# R7FA4L1BD register map
Vendor: Renesas Electronics Corporation; Series: RA4; File version: 1.20.03
CPU: CM33 r0p4, little endian, MPU, FPU, VTOR, 4 interrupt priority bits, 96 interrupts
Registers are 32-bit, read-write, reset 0x0 unless marked. A register's access mark holds for its fields unless they carry their own. Offsets are from the block's base; [hi:lo] are bit positions; {n}, {i} and the like mark numbered series; 'fields as' and 'values as' point back to an identical list.

## CACHE
Base 0x40007000
0x00 CCACTL — C-Cache Control Register
  [0] ENC — C-Cache Enable
    0=Disable C-cache; 1=Enable C-cache
0x04 CCAFCT — C-Cache Flush Control Register
  [0] FC — C-Cache Flush
    0=No action; 1=C-cache line flush (all lines invalidated)
0x08 CCALCF reset 0x1 — C-Cache Line Configuration Register
  [1:0] CC — C-Cache Line Size
    0=Prohibited; 1=Cache line size 32 bytes; 2=Cache line size 64 bytes; 3=Prohibited
0x40 SCACTL — S-Cache Control Register
  [0] ENS — S-Cache Enable
    0=Disable S-cache; 1=Enable S-cache
0x44 SCAFCT — S-Cache Flush Control Register
  [0] FS — S-Cache Flush
    0=No action; 1=S-cache line flush (all lines invalidated)
0x48 SCALCF reset 0x1 — S-Cache Line Configuration Register
  [1:0] CS — S-Cache Line Size
    values as CCALCF.CC
0x200 CAPOAD — Cache Parity Error Operation After Detection Register
  [0] OAD — Operation after Detection
    0=Non-maskable interrupt; 1=Reset
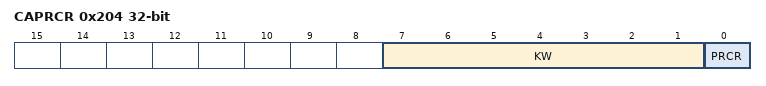
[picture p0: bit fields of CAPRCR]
0x204 CAPRCR — Cache Protection Register
  [7:1] KW — Write key code
  [0] PRCR — Register Write Control
    0=Disable writes to protected registers; 1=Enable writes to protected registers

## DBG — Debug Function
Base 0x4001B000
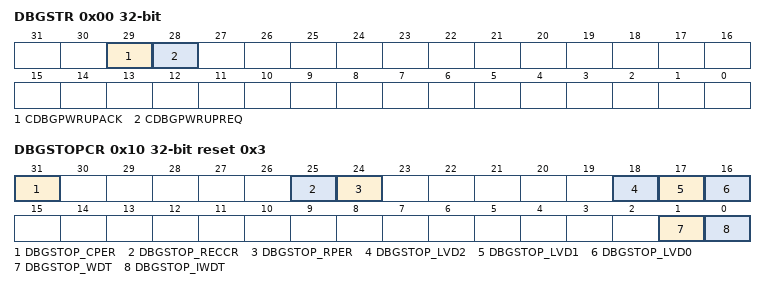
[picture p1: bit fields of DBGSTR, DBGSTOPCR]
0x00 DBGSTR ro — Debug Status Register
  [29] CDBGPWRUPACK — Debug power-up acknowledge
    0=Debug power-up request is not acknowledged; 1=Debug power-up request is acknowledged
  [28] CDBGPWRUPREQ — Debug power-up request
    0=OCD is not requesting debug power up; 1=OCD is requesting debug power up
0x10 DBGSTOPCR reset 0x3 — Debug Stop Control Register
  [31] DBGSTOP_CPER — Mask bit for Cache SRAM parity error reset/interrupt
    0=Enable Cache SRAM parity error reset/interrupt; 1=Mask Cache SRAM parity error reset/interrupt
  [25] DBGSTOP_RECCR — Mask bit for SRAM ECC error reset/interrupt
    0=Enable SRAM ECC error reset/interrupt; 1=Mask SRAM ECC error reset/interrupt
  [24] DBGSTOP_RPER — Mask bit for SRAM parity error reset/interrupt
    0=Enable SRAM parity error reset/interrupt; 1=Mask SRAM parity error reset/interrupt
  [18] DBGSTOP_LVD2 — Mask bit for LVD2 reset/interrupt
    0=Enable LVD2 reset/interrupt; 1=Mask LVD2 reset/interrupt
  [17] DBGSTOP_LVD1 — Mask bit for LVD1 reset/interrupt
    0=Enable LVD1 reset/interrupt; 1=Mask LVD1 reset/interrupt
  [16] DBGSTOP_LVD0 — Mask bit for LVD0 reset
    0=Enable LVD0 reset; 1=Mask LVD0 reset
  [1] DBGSTOP_WDT — Mask bit for WDT reset/interrupt in the OCD run mode
    0=Enable WDT reset/interrupt; 1=Mask WDT reset/interrupt and stop WDT counter
  [0] DBGSTOP_IWDT — Mask bit for IWDT reset/interrupt in the OCD run mode
    0=Enable IWDT reset/interrupt; 1=Mask IWDT reset/interrupt and stop IWDT counter

## FCACHE — SYSTEM/FLASH
Base 0x4001C100
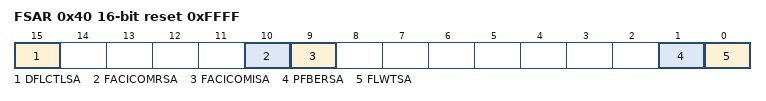
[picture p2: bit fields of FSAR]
0x40 FSAR 16-bit reset 0xFFFF — Flash Security Attribution Register
  [all] fields
    0=Secure; 1=Non-secure
  [15] DFLCTLSA — DFLCTL Security Attribution
  [10] FACICOMRSA — FACI Command Registers Security Attribution
  [9] FACICOMISA — FACI Command Issuing Security Attribution
  [1] PFBERSA — PFBER Security Attribution
  [0] FLWTSA — FLWT Security Attribution

## PORT0 — Pmn Pin FunctionPort 0 Control RegistersPmn Pin Function Control Register
Base 0x4001F000
Same registers: PORT5 0x4001F0A0, PORT8 0x4001F100
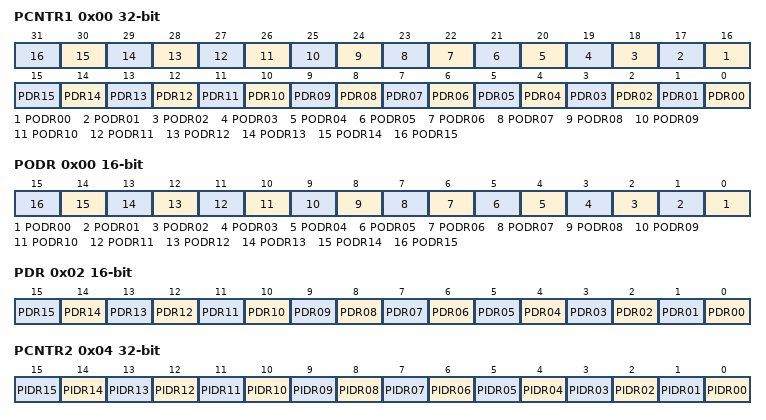
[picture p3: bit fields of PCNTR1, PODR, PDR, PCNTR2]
0x00 PCNTR1 — Port Control Register 1
  [n+16] PODR{n:02} (n=0..15) — Pmn Output Data
    0=Low output; 1=High output
  [n] PDR{n:02} (n=0..15) — Pmn Direction
    0=Input (functions as an input pin); 1=Output (functions as an output pin)
0x00 PODR 16-bit (alternate view of PCNTR1) — Port Control Register 1
  [all] fields
    0=Low output; 1=High output
  [n] PODR{n:02} (n=0..15) — Pmn Output Data
0x02 PDR 16-bit (alternate view of PCNTR1) — Port Control Register 1
  [all] fields
    values as PCNTR1.PDR00
  [n] PDR{n:02} (n=0..15) — Pmn Direction
0x04 PCNTR2 ro (reset mask 0xFFFF0000) — Port Control Register 2
  [all] fields
    0=Low level; 1=High level
  [n] PIDR{n:02} (n=0..15) — Pmn State
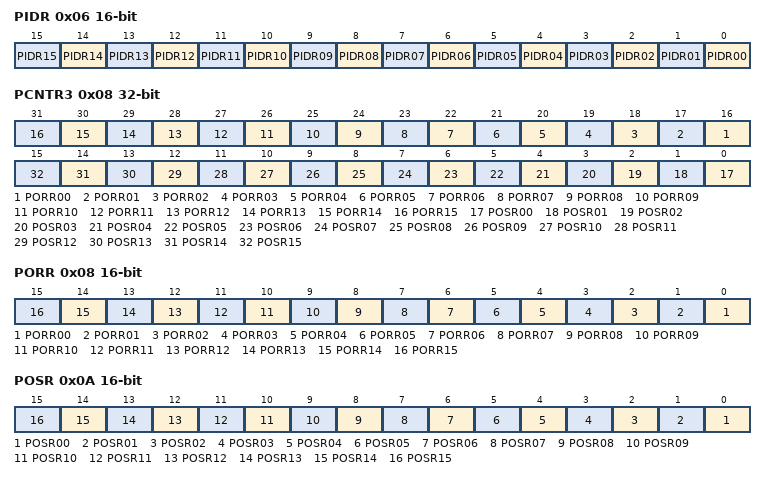
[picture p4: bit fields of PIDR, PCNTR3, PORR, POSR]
0x06 PIDR 16-bit ro reset not defined (alternate view of PCNTR2) — Port Control Register 2
  fields as PCNTR2
0x08 PCNTR3 wo — Port Control Register 3
  [n+16] PORR{n:02} (n=0..15) — Pmn Output Reset
    0=No effect on output; 1=Low output
  [n] POSR{n:02} (n=0..15) — Pmn Output Set
    0=No effect on output; 1=High output
0x08 PORR 16-bit wo (alternate view of PCNTR3) — Port Control Register 3
  [all] fields
    0=No effect on output; 1=Low output
  [n] PORR{n:02} (n=0..15) — Pmn Output Reset
0x0A POSR 16-bit wo (alternate view of PCNTR3) — Port Control Register 3
  [all] fields
    0=No effect on output; 1=High output
  [n] POSR{n:02} (n=0..15) — Pmn Output Set

## PORT1 — Pmn Pin FunctionPort 1 Control RegistersPmn Pin Function Control Register
Base 0x4001F020
Same registers: PORT2 0x4001F040, PORT3 0x4001F060, PORT4 0x4001F080
Registers as PORT0; these are added or differ:
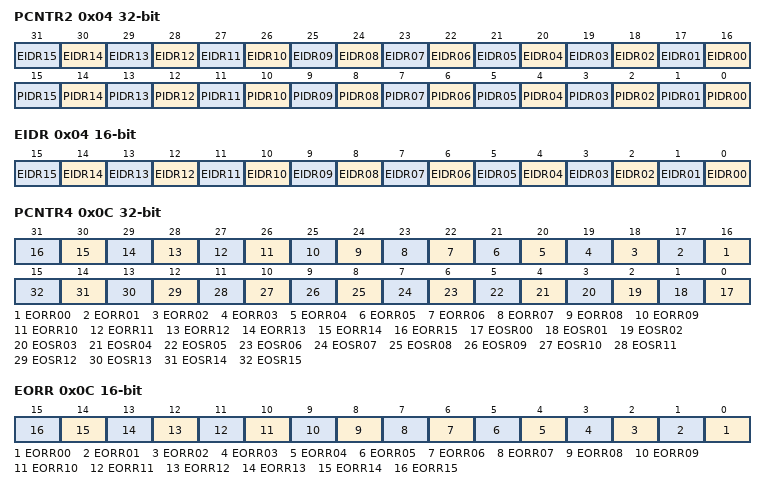
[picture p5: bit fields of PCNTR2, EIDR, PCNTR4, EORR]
0x04 PCNTR2 ro (reset mask 0xFFFF0000) — Port Control Register 2
  [n+16] EIDR{n:02} (n=0..15) — Port Event Input Data
    0=Low input; 1=High input
  [n] PIDR{n:02} (n=0..15) — Pmn State
    0=Low level; 1=High level
0x04 EIDR 16-bit ro (alternate view of PCNTR2) — Port Control Register 2
  [all] fields
    0=Low input; 1=High input
  [n] EIDR{n:02} (n=0..15) — Port Event Input Data
0x0C PCNTR4 — Port Control Register 4
  [n+16] EORR{n:02} (n=0..15) — Pmn Event Output Reset
    0=No effect on output; 1=Low output
  [n] EOSR{n:02} (n=0..15) — Pmn Event Output Set
    0=No effect on output; 1=High output
0x0C EORR 16-bit (alternate view of PCNTR4) — Port Control Register 4
  [all] fields
    0=No effect on output; 1=Low output
  [n] EORR{n:02} (n=0..15) — Pmn Event Output Reset
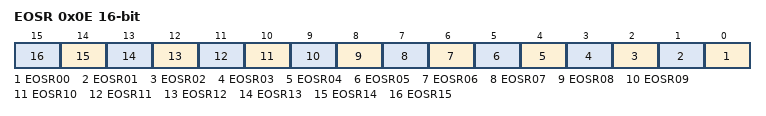
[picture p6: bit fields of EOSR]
0x0E EOSR 16-bit (alternate view of PCNTR4) — Port Control Register 4
  [all] fields
    0=No effect on output; 1=High output
  [n] EOSR{n:02} (n=0..15) — Pmn Event Output Set

## Notices in the file
This software is supplied by Renesas Electronics Corporation and is only intended for
use with Renesas products. No other uses are authorized. This software is owned by
Renesas Electronics Corporation and is protected under all applicable laws, including
copyright laws.
THIS SOFTWARE IS PROVIDED "AS IS" AND RENESAS MAKES NO WARRANTIES REGARDING
THIS SOFTWARE, WHETHER EXPRESS, IMPLIED OR STATUTORY, INCLUDING BUT NOT LIMITED TO
WARRANTIES OF MERCHANTABILITY, FITNESS FOR A PARTICULAR PURPOSE AND NON-INFRINGEMENT.
ALL SUCH WARRANTIES ARE EXPRESSLY DISCLAIMED. TO THE MAXIMUM EXTENT PERMITTED NOT
PROHIBITED BY LAW, NEITHER RENESAS ELECTRONICS CORPORATION NOR ANY OF ITS AFFILIATED
COMPANIES SHALL BE LIABLE FOR ANY DIRECT, INDIRECT, SPECIAL, INCIDENTAL OR CONSEQUENTIAL
DAMAGES FOR ANY REASON RELATED TO THIS SOFTWARE, EVEN IF RENESAS OR ITS AFFILIATES HAVE
BEEN ADVISED OF THE POSSIBILITY OF SUCH DAMAGES.
Renesas reserves the right, without notice, to make changes to this software and to
discontinue the availability of this software. By using this software, you agree to
the additional terms and conditions found by accessing the following link:
http://www.renesas.com/disclaimer
